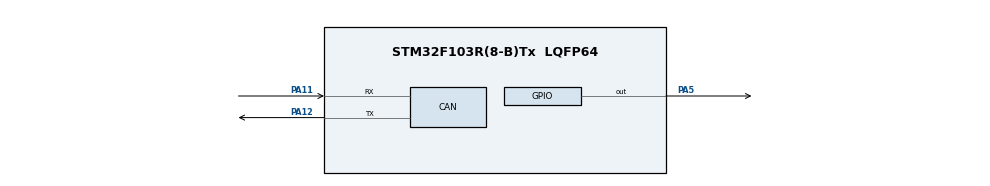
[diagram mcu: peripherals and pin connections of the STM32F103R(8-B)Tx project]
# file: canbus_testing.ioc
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CAN.CalculateTimeBit=6000
CAN.CalculateTimeQuantum=2000.0
Mcu.Family=STM32F1
Mcu.Name=STM32F103R(8-B)Tx
Mcu.Package=LQFP64
NVIC.PriorityGroup=NVIC_PRIORITYGROUP_4
PA11.Mode=Master
PA11.Signal=CAN_RX
PA12.Mode=Master
PA12.Signal=CAN_TX
PA13.Mode=Serial_Wire
PA13.Signal=SYS_JTMS-SWDIO
PA14.Mode=Serial_Wire
PA14.Signal=SYS_JTCK-SWCLK
PA5.Signal=GPIO_Output
ProjectManager.HeapSize=0x200
ProjectManager.StackSize=0x400
ProjectManager.TargetToolchain=SW4STM32
RCC.APB1Freq_Value=8000000
RCC.APB2Freq_Value=8000000
board=custom

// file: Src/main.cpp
/**
  ******************************************************************************
  * @file           : main.c
  * @brief          : Main program body
  ******************************************************************************
  ** This notice applies to any and all portions of this file
  * that are not between comment pairs USER CODE BEGIN and
  * USER CODE END. Other portions of this file, whether
  * inserted by the user or by software development tools
  * are owned by their respective copyright owners.
  *
  * COPYRIGHT(c) 2018 STMicroelectronics
  *
  * Redistribution and use in source and binary forms, with or without modification,
  * are permitted provided that the following conditions are met:
  *   1. Redistributions of source code must retain the above copyright notice,
  *      this list of conditions and the following disclaimer.
  *   2. Redistributions in binary form must reproduce the above copyright notice,
  *      this list of conditions and the following disclaimer in the documentation
  *      and/or other materials provided with the distribution.
  *   3. Neither the name of STMicroelectronics nor the names of its contributors
  *      may be used to endorse or promote products derived from this software
  *      without specific prior written permission.
  *
  * THIS SOFTWARE IS PROVIDED BY THE COPYRIGHT HOLDERS AND CONTRIBUTORS "AS IS"
  * AND ANY EXPRESS OR IMPLIED WARRANTIES, INCLUDING, BUT NOT LIMITED TO, THE
  * IMPLIED WARRANTIES OF MERCHANTABILITY AND FITNESS FOR A PARTICULAR PURPOSE ARE
  * DISCLAIMED. IN NO EVENT SHALL THE COPYRIGHT HOLDER OR CONTRIBUTORS BE LIABLE
  * FOR ANY DIRECT, INDIRECT, INCIDENTAL, SPECIAL, EXEMPLARY, OR CONSEQUENTIAL
  * DAMAGES (INCLUDING, BUT NOT LIMITED TO, PROCUREMENT OF SUBSTITUTE GOODS OR
  * SERVICES; LOSS OF USE, DATA, OR PROFITS; OR BUSINESS INTERRUPTION) HOWEVER
  * CAUSED AND ON ANY THEORY OF LIABILITY, WHETHER IN CONTRACT, STRICT LIABILITY,
  * OR TORT (INCLUDING NEGLIGENCE OR OTHERWISE) ARISING IN ANY WAY OUT OF THE USE
  * OF THIS SOFTWARE, EVEN IF ADVISED OF THE POSSIBILITY OF SUCH DAMAGE.
  *
  ******************************************************************************
  */

#include "main.h"
#include "stm32f1xx_hal.h"
#include "stm32f1xx_it.h"

#include <uavcan_stm32/uavcan_stm32.hpp>
#include <app/subscribers.hpp>
#include <app/publishers.hpp>

CAN_HandleTypeDef hcan;

/* USER CODE BEGIN PV */
/* Private variables ---------------------------------------------------------*/

#define SENDER

#ifdef SENDER
static const char node_id = 10;
static char * node_name = "Terminal Sender";
#endif

#ifdef RECEIVER
static const char node_id = 20;
static char* node_name = "Terminal Receiver";
#endif
/* USER CODE END PV */

extern "C" {
	void SystemClock_Config(void);
	static void MX_GPIO_Init(void);
	static void MX_CAN_Init(void);
}

/* USER CODE BEGIN PFP */
/* Private function prototypes -----------------------------------------------*/

/* USER CODE END PFP */

int main(void)
{

  /* MCU Configuration----------------------------------------------------------*/

  /* Reset of all peripherals, Initializes the Flash interface and the Systick. */
  HAL_Init();

  /* Configure the system clock */
  SystemClock_Config();
  SysTick_Handler();

  /* Initialize all configured peripherals */
  MX_GPIO_Init();
  MX_CAN_Init();

  /* Infinite loop */
  /* USER CODE BEGIN WHILE */

  uavcan::protocol::HardwareVersion hw_ver;
  hw_ver.major = 0;
  hw_ver.minor = 0;
  uavcan::protocol::SoftwareVersion sw_ver;
  sw_ver.major = 0;
  sw_ver.minor = 0;

  uavcan_init(node_id, node_name, hw_ver, sw_ver);

#ifdef SENDER
  publishers_init();
#endif

#ifdef RECEIVER
  subscribers_init();
#endif

  uavcan_setOperational();

  HAL_Delay(2000);

  while (1) {
#ifdef SENDER
	  publish_NodeStatus(0, 0, 42);
	  HAL_GPIO_WritePin(GPIOA, GPIO_PIN_5, GPIO_PIN_SET);
	  //HAL_Delay(500);
	  HAL_GPIO_WritePin(GPIOA, GPIO_PIN_5, GPIO_PIN_RESET);
#endif

#ifdef RECEIVER
	  uavcan_spin_ms(500);
	  if (is_node_operational) {
		  HAL_GPIO_WritePin(GPIOA, GPIO_PIN_5, GPIO_PIN_SET);
		  delay_ms(50);
		  HAL_GPIO_WritePin(GPIOA, GPIO_PIN_5, GPIO_PIN_RESET);
	  }
#endif
  }

}

extern "C" {

void SystemClock_Config(void)
{

  RCC_OscInitTypeDef RCC_OscInitStruct;
  RCC_ClkInitTypeDef RCC_ClkInitStruct;

    /**Initializes the CPU, AHB and APB busses clocks
    */
  RCC_OscInitStruct.OscillatorType = RCC_OSCILLATORTYPE_HSI;
  RCC_OscInitStruct.HSIState = RCC_HSI_ON;
  RCC_OscInitStruct.HSICalibrationValue = 16;
  RCC_OscInitStruct.PLL.PLLState = RCC_PLL_NONE;
  if (HAL_RCC_OscConfig(&RCC_OscInitStruct) != HAL_OK)
  {
    _Error_Handler(__FILE__, __LINE__);
  }

    /**Initializes the CPU, AHB and APB busses clocks
    */
  RCC_ClkInitStruct.ClockType = RCC_CLOCKTYPE_HCLK|RCC_CLOCKTYPE_SYSCLK
                              |RCC_CLOCKTYPE_PCLK1|RCC_CLOCKTYPE_PCLK2;
  RCC_ClkInitStruct.SYSCLKSource = RCC_SYSCLKSOURCE_HSI;
  RCC_ClkInitStruct.AHBCLKDivider = RCC_SYSCLK_DIV1;
  RCC_ClkInitStruct.APB1CLKDivider = RCC_HCLK_DIV1;
  RCC_ClkInitStruct.APB2CLKDivider = RCC_HCLK_DIV1;

  if (HAL_RCC_ClockConfig(&RCC_ClkInitStruct, FLASH_LATENCY_0) != HAL_OK)
  {
    _Error_Handler(__FILE__, __LINE__);
  }

    /**Configure the Systick interrupt time
    */
  HAL_SYSTICK_Config(HAL_RCC_GetHCLKFreq()/1000);

    /**Configure the Systick
    */
  HAL_SYSTICK_CLKSourceConfig(SYSTICK_CLKSOURCE_HCLK);

  /* SysTick_IRQn interrupt configuration */
  HAL_NVIC_SetPriority(SysTick_IRQn, 0, 0);
}

/* CAN init function */
static void MX_CAN_Init(void)
{

  hcan.Instance = CAN1;
  hcan.Init.Prescaler = 16;
  hcan.Init.Mode = CAN_MODE_NORMAL;
  hcan.Init.SJW = CAN_SJW_1TQ;
  hcan.Init.BS1 = CAN_BS1_1TQ;
  hcan.Init.BS2 = CAN_BS2_1TQ;
  hcan.Init.TTCM = DISABLE;
  hcan.Init.ABOM = DISABLE;
  hcan.Init.AWUM = DISABLE;
  hcan.Init.NART = DISABLE;
  hcan.Init.RFLM = DISABLE;
  hcan.Init.TXFP = DISABLE;
  if (HAL_CAN_Init(&hcan) != HAL_OK)
  {
    _Error_Handler(__FILE__, __LINE__);
  }

}

/** Configure pins as
        * Analog
        * Input
        * Output
        * EVENT_OUT
        * EXTI
*/
static void MX_GPIO_Init(void)
{

  GPIO_InitTypeDef GPIO_InitStruct;

  /* GPIO Ports Clock Enable */
  __HAL_RCC_GPIOA_CLK_ENABLE();

  /*Configure GPIO pin Output Level */
  HAL_GPIO_WritePin(GPIOA, GPIO_PIN_5, GPIO_PIN_RESET);

  /*Configure GPIO pin : PA5 */
  GPIO_InitStruct.Pin = GPIO_PIN_5;
  GPIO_InitStruct.Mode = GPIO_MODE_OUTPUT_PP;
  GPIO_InitStruct.Pull = GPIO_NOPULL;
  GPIO_InitStruct.Speed = GPIO_SPEED_FREQ_LOW;
  HAL_GPIO_Init(GPIOA, &GPIO_InitStruct);

}

void _Error_Handler(char *file, int line)
{
  while(1)
  {
  }
}

}

/************************ (C) COPYRIGHT STMicroelectronics *****END OF FILE****/
